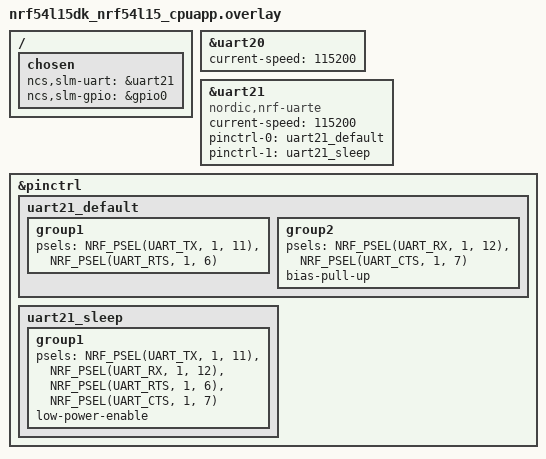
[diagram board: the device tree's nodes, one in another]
/*
 * Copyright (c) 2023 Nordic Semiconductor ASA
 *
 * SPDX-License-Identifier: LicenseRef-Nordic-5-Clause
 */

/ {
	chosen {
		ncs,slm-uart = &uart21;
		ncs,slm-gpio = &gpio0;
	};
};

/* Shell UART */
&uart20 {
	current-speed = <115200>;
	status = "okay";
};

/* SLM Shell <-> SLM UART */
&uart21 {
	compatible = "nordic,nrf-uarte";
	current-speed = <115200>;
	status = "okay";
	/*hw-flow-control;*/
	pinctrl-0 = <&uart21_default>;
	pinctrl-1 = <&uart21_sleep>;
	pinctrl-names = "default", "sleep";
};

/* P1.06 UART1_RST/P1.07 UART1_CTS available when VCOM1 HWFC is disabled */
&pinctrl {
	uart21_default: uart21_default {
		group1 {
			psels = <NRF_PSEL(UART_TX, 1, 11)>,
				<NRF_PSEL(UART_RTS, 1, 6)>;
		};
		group2 {
			psels = <NRF_PSEL(UART_RX, 1, 12)>,
				<NRF_PSEL(UART_CTS, 1, 7)>;
			bias-pull-up;
		};
	};

	uart21_sleep: uart21_sleep {
		group1 {
			psels = <NRF_PSEL(UART_TX, 1, 11)>,
				<NRF_PSEL(UART_RX, 1, 12)>,
				<NRF_PSEL(UART_RTS, 1, 6)>,
				<NRF_PSEL(UART_CTS, 1, 7)>;
			low-power-enable;
		};
	};
};
